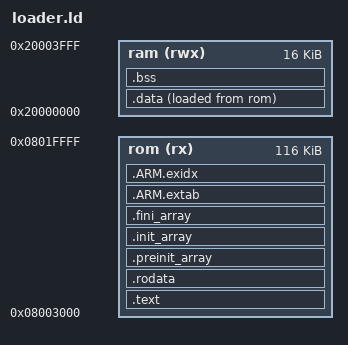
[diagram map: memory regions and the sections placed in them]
MEMORY
{
  /* Devo7e-256 has 256K, and bootloader takes up 12K */
  rom (rx) : ORIGIN = 0x08003000, LENGTH = 116K
  ram (rwx) : ORIGIN = 0x20000000, LENGTH = 16K
}

/* Enforce emmition of the vector table. */
EXTERN (small_vector_table)

/* Enforce emmission of the tx string. */
EXTERN (txver)

/* Define the entry point of the output file. */
ENTRY(reset_handler)

/* Define sections. */
SECTIONS
{
	.text : {
		*(.smallvectors)	/* Vector table */
		. = 0x3000;
		*(.text*)		/* Program code */
	} >rom
	.rodata :{
		. = ALIGN(4);
		*(.rodata*)	/* Read-only data */
	} >rom
	/* C++ Static constructors/destructors, also used for __attribute__
	 * ((constructor)) and the likes */
	.preinit_array : {
		. = ALIGN(4);
		__preinit_array_start = .;
		KEEP (*(.preinit_array))
		__preinit_array_end = .;
	} >rom
	.init_array : {
		. = ALIGN(4);
		__init_array_start = .;
		KEEP (*(SORT(.init_array.*)))
		KEEP (*(.init_array))
		__init_array_end = .;
	} >rom
	.fini_array : {
		. = ALIGN(4);
		__fini_array_start = .;
		KEEP (*(.fini_array))
		KEEP (*(SORT(.fini_array.*)))
		__fini_array_end = .;
	} >rom

	/*
	 * Another section used by C++ stuff, appears when using newlib with
	 * 64bit (long long) printf support
	 */
	.ARM.extab : {
		*(.ARM.extab*)
	} >rom
	.ARM.exidx : {
		__exidx_start = .;
		*(.ARM.exidx*)
		__exidx_end = .;
	} >rom

	. = ALIGN(4);
	_etext = .;

	.data : {
		_data = .;
		*(.data*)	/* Read-write initialized data */
		. = ALIGN(4);
		_edata = .;
	} >ram AT >rom
	_data_loadaddr = LOADADDR(.data);

	.bss : {
		*(.bss*)	/* Read-write zero initialized data */
		*(COMMON)
		. = ALIGN(4);
		_ebss = .;
	} >ram

	/*
	 * The .eh_frame section appears to be used for C++ exception handling.
	 * You may need to fix this if you're using C++.
	 */
	/DISCARD/ : { *(.eh_frame) }

	. = ALIGN(4);
	end = .;
}

PROVIDE(_stack = ORIGIN(ram) + LENGTH(ram));

